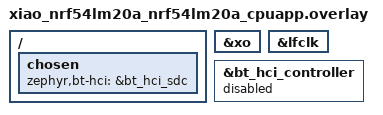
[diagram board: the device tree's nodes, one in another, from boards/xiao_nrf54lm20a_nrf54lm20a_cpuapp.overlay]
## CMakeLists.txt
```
# Copyright (c) 2026 Nordic Semiconductor ASA
#
# SPDX-License-Identifier: Apache-2.0

cmake_minimum_required(VERSION 3.20.0)

find_package(Zephyr REQUIRED HINTS $ENV{ZEPHYR_BASE})
project(bap_broadcast_assistant_display)

target_sources(app PRIVATE
  src/main.c
  src/ble_scan_ctrl.c
  src/ui.c
  src/nordic_logo.c
)
```

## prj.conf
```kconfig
# Copyright (c) 2026 Nordic Semiconductor ASA
#
# SPDX-License-Identifier: Apache-2.0

# General
CONFIG_LOG=y
CONFIG_MAIN_STACK_SIZE=8192
CONFIG_SYSTEM_WORKQUEUE_STACK_SIZE=4096

# Nordic's own reference boards for this SoC (nrf54lm20dk, nrf54l15dk) enable
# this by default in their board Kconfig.defconfig ("default
# ARCH_HAS_STACK_PROTECTION"); the XIAO board port never added that default,
# so a stack overflow on this board silently corrupts adjacent memory instead
# of being caught cleanly - manifesting as a confusing crash far from the
# actual cause (observed: "USAGE FAULT: Illegal load of EXC_RETURN into PC").
# Enabling it here turns any future overflow into a clear "stack overflow"
# fatal error instead.
CONFIG_HW_STACK_PROTECTION=y

# Bluetooth core
CONFIG_BT=y
CONFIG_BT_DEVICE_NAME="NCS Broadcast Assistant"
CONFIG_BT_CENTRAL=y
CONFIG_BT_GATT_CLIENT=y
CONFIG_BT_GATT_AUTO_DISCOVER_CCC=y
CONFIG_BT_GATT_AUTO_UPDATE_MTU=y
CONFIG_BT_SMP=y
CONFIG_BT_BUF_ACL_RX_SIZE=255
CONFIG_BT_BUF_ACL_TX_SIZE=251

# Both default to 1. Sinks stay connected once picked - toggling one between
# receiving and not receiving the source reuses its existing connection
# rather than reconnecting - so multiple sinks can be connected (and bonded)
# at once. Sized to BLE_SCAN_CTRL_MAX_SINK_CONN in ble_scan_ctrl.h, the most
# sinks this sample will ever try to hold open at the same time. Observed on
# hardware before this was raised: bonding a second sink while a first bond
# was still held failed synchronously with -ENOMEM.
CONFIG_BT_MAX_CONN=4
CONFIG_BT_MAX_PAIRED=4

# Explicitly require the Nordic SoftDevice Controller. This SoC's
# devicetree (plus boards/xiao_nrf54lm20a_nrf54lm20a_cpuapp.overlay, which
# disables the alternative &bt_hci_controller node) already makes this the
# Kconfig default, but pinning it here makes the choice self-documenting
# and keeps the build from silently falling back to Zephyr's open-source
# BT_LL_SW_SPLIT controller if the devicetree ever changes.
CONFIG_BT_LL_SOFTDEVICE=y
# Not CONFIG_BT_CTLR_SCAN_DATA_LEN_MAX: that symbol belongs to BT_LL_SW_SPLIT
# only, and does not apply to the SoftDevice Controller.

# LE Audio: Broadcast Assistant (BASS client) role
# CONFIG_UTF8 and CONFIG_BT_AUDIO gate the whole subsys/bluetooth/audio
# Kconfig tree (see zephyr/subsys/bluetooth/audio/Kconfig: "menuconfig
# BT_AUDIO depends on UTF8" followed by "if BT_AUDIO" wrapping Kconfig.bap).
# Without them, BT_BAP_BASS_MAX_SUBGROUPS and
# BT_AUDIO_CODEC_CFG_MAX_METADATA_SIZE below are never defined, which is
# why the build failed.
CONFIG_UTF8=y
CONFIG_BT_AUDIO=y
CONFIG_BT_EXT_ADV=y
CONFIG_BT_PER_ADV_SYNC=y
CONFIG_BT_ISO_SYNC_RECEIVER=y
CONFIG_BT_BAP_BROADCAST_ASSISTANT=y
CONFIG_BT_BAP_BASS_MAX_SUBGROUPS=2
CONFIG_BT_AUDIO_CODEC_CFG_MAX_METADATA_SIZE=255

# Display + touch input
CONFIG_DISPLAY=y
CONFIG_INPUT=y

# Real-time clock (PCF8563, wired up by the seeed_xiao_round_display shield's
# devicetree and aliased as "rtc") backing the idle clock screen.
CONFIG_RTC=y

# LVGL
CONFIG_LVGL=y
CONFIG_LV_Z_LVGL_MUTEX=y
CONFIG_LV_Z_MEM_POOL_SIZE=49152
CONFIG_LV_COLOR_DEPTH_16=y
CONFIG_LV_USE_LABEL=y
CONFIG_LV_USE_LIST=y
CONFIG_LV_USE_FLEX=y
CONFIG_LV_USE_BUTTON=y
CONFIG_LV_USE_BUTTONMATRIX=y
CONFIG_LV_USE_TEXTAREA=y
CONFIG_LV_USE_KEYBOARD=y
CONFIG_LV_USE_IMAGE=y
CONFIG_LV_USE_LINE=y
CONFIG_LV_FONT_MONTSERRAT_14=y
CONFIG_LV_FONT_MONTSERRAT_24=y
CONFIG_LV_FONT_DEFAULT_MONTSERRAT_14=y
```

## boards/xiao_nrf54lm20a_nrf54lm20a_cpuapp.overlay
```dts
/*
 * Copyright (c) 2026 Nordic Semiconductor ASA
 *
 * SPDX-License-Identifier: Apache-2.0
 */

/*
 * The XIAO nRF54LM20A board files (as of this NCS/Zephyr checkout) enable
 * &clock, &radio, &bt_hci_controller and &lfxo, but never set &xo or &lfclk
 * to "okay". The open-source Bluetooth Link Layer controller
 * (subsys/bluetooth/controller/ll_sw/nordic/lll/lll_clock.c) reads the
 * &lfclk node's "k32src-accuracy-ppm" property at compile time via a
 * DT_ENUM_IDX()-style macro; since the node is disabled it never appears in
 * the generated devicetree headers, so that macro is undeclared and the
 * build fails ("'__P_k32src_accuracy_ppm_IDX_0_ENUM_IDX' undeclared").
 *
 * Nordic's own reference boards for the same SoC (nrf54lm20dk, nrf54l15dk)
 * enable both nodes in their board devicetree; this overlay applies the same
 * fix at the application level without touching the shared board files.
 */

&xo {
	status = "okay";
};

&lfclk {
	status = "okay";
};

/*
 * zephyr/dts/arm/nordic/nrf54lm20_a_b_cpuapp.dtsi already enables
 * &bt_hci_sdc (the Nordic SoftDevice Controller) by default for this SoC.
 * The board's own nrf54lm20a_cpuapp_common.dtsi additionally enables
 * &bt_hci_controller (Zephyr's open-source software Link Layer controller,
 * compatible "zephyr,bt-hci-ll-sw-split"). With both devicetree nodes
 * "okay", Kconfig independently defaults BOTH CONFIG_BT_LL_SOFTDEVICE and
 * CONFIG_BT_LL_SW_SPLIT to y (nothing makes them mutually exclusive), so
 * both controller implementations get compiled and linked together and
 * collide on the same symbols (bt_ctlr_set_public_addr, bt_rand,
 * bt_encrypt_le/be): "multiple definition of `bt_ctlr_set_public_addr'".
 *
 * Disable the redundant open-source controller so only the SoftDevice
 * Controller (the production controller Nordic ships for this SoC) is
 * built.
 */
&bt_hci_controller {
	status = "disabled";
};

/*
 * nrf54lm20a_cpuapp_common.dtsi sets chosen "zephyr,bt-hci" to
 * &bt_hci_controller, which we just disabled above. Left unchanged, that
 * chosen property still points at a disabled node with no device instance,
 * so zephyr/subsys/bluetooth/host/hci_core.c's DEVICE_DT_GET(DT_CHOSEN(
 * zephyr_bt_hci)) fails to find the generated device: "'__device_dts_ord_N'
 * undeclared". Point it at &bt_hci_sdc instead, matching the controller we
 * actually kept enabled.
 */
/ {
	chosen {
		zephyr,bt-hci = &bt_hci_sdc;
	};
};
```

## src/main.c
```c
/*
 * Copyright (c) 2026 Nordic Semiconductor ASA
 *
 * SPDX-License-Identifier: Apache-2.0
 */

/**
 * @file
 * @brief Broadcast Assistant sample with a touch UI on a round display.
 *
 * Flow:
 *   0. Boots into an idle clock screen (Nordic logo + time). Tapping it
 *      starts scanning.
 *   1. Scan for Broadcast Sources and show them on screen.
 *   2. User taps a source -> periodic advertising sync to it starts in the
 *      background, and the UI switches to scanning for Broadcast Sinks.
 *      Tapping Exit at any point during 1-3 stops scanning/disconnects and
 *      returns to the clock screen.
 *   3. User taps a sink -> we connect to it, discover its Broadcast Audio
 *      Scan Service, and (once the source's BASE has been received) add the
 *      selected source to it, so the sink starts receiving the broadcast;
 *      it shows up greyed out and stays connected. Sink scanning keeps
 *      running, so more sinks can be picked the same way.
 *   4. Tapping a greyed-out sink removes the source from it over the same
 *      connection (no reconnect), so it stops receiving and goes back to
 *      being selectable. Tapping it again adds the source back. Either way
 *      the sink stays connected the whole time.
 */

#include <errno.h>
#include <stdbool.h>
#include <stdint.h>

#include <zephyr/kernel.h>
#include <zephyr/logging/log.h>

#include "ble_scan_ctrl.h"
#include "ui.h"

LOG_MODULE_REGISTER(app, LOG_LEVEL_INF);

#define UI_POLL_PERIOD	   K_MSEC(10)
#define SPLASH_DURATION_MS 2000U

static void handle_row_selected(enum ui_screen screen, uint8_t index);
static void handle_clock_tapped(void);
static void handle_exit(void);
static void handle_source_found(uint8_t index, const struct ble_broadcast_source *source);
static void handle_sink_found(uint8_t index, const struct ble_broadcast_sink *sink);
static void handle_sink_connected(uint8_t index);
static void handle_sink_disconnected(uint8_t index);
static void handle_source_synced(void);
static void handle_source_added(uint8_t index);
static void handle_source_removed(uint8_t index);
static void handle_op_failed(enum ble_scan_ctrl_op op, uint8_t sink_index, int err);

static const struct ble_scan_ctrl_cb ble_callbacks = {
	.source_found = handle_source_found,
	.sink_found = handle_sink_found,
	.sink_connected = handle_sink_connected,
	.sink_disconnected = handle_sink_disconnected,
	.source_synced = handle_source_synced,
	.source_added = handle_source_added,
	.source_removed = handle_source_removed,
	.op_failed = handle_op_failed,
};

/** Drop all BLE state and restart the whole demo from the source-scan screen. */
static void restart_demo(void)
{
	int ret;

	(void)ble_scan_ctrl_reset();
	ui_show_source_list();

	ret = ble_scan_ctrl_start_source_scan();
	if (ret != 0) {
		LOG_ERR("Failed to start source scan (ret %d)", ret);
		ui_show_status("Scan error", "Could not start source scan");
	}
}

/** True for failures that mean the selected source itself is gone, not just one sink. */
static bool op_is_source_level(enum ble_scan_ctrl_op op)
{
	return op == BLE_SCAN_CTRL_OP_SOURCE_SCAN || op == BLE_SCAN_CTRL_OP_SOURCE_PA_SYNC;
}

static void handle_row_selected(enum ui_screen screen, uint8_t index)
{
	int ret;

	switch (screen) {
	case UI_SCREEN_SOURCE_LIST:
		ret = ble_scan_ctrl_select_source(index);
		if (ret != 0) {
			LOG_ERR("Failed to select source %u (ret %d)", index, ret);
			ui_show_status("Selection failed", "Could not select that source");
			return;
		}

		LOG_INF("Source %u selected; scanning for sinks", index);
		ui_show_sink_list();

		ret = ble_scan_ctrl_start_sink_scan();
		if (ret != 0) {
			LOG_ERR("Failed to start sink scan (ret %d)", ret);
			ui_show_status("Scan error", "Could not start sink scan");
		}
		break;

	case UI_SCREEN_SINK_LIST:
		/* Connects a never-seen sink, or toggles an already-connected one between
		 * receiving and not receiving the source - see ble_scan_ctrl_select_sink().
		 * Every outcome (including failure) arrives later via one of the
		 * ble_callbacks below, keyed by sink index, so there is nothing to do here
		 * beyond starting it and quietly dropping a redundant tap.
		 */
		ret = ble_scan_ctrl_select_sink(index);
		if (ret == -EBUSY) {
			LOG_WRN("Sink %u already has an operation in progress", index);
		} else if (ret != 0) {
			LOG_ERR("Failed to toggle sink %u (ret %d)", index, ret);
		}
		break;

	case UI_SCREEN_CLOCK:
	case UI_SCREEN_STATUS:
	default:
		/* No tappable rows on these screens; nothing to do. */
		break;
	}
}

static void handle_clock_tapped(void)
{
	LOG_INF("Clock tapped; starting scan");
	restart_demo();
}

static void handle_exit(void)
{
	LOG_INF("Exit tapped; returning to clock");
	(void)ble_scan_ctrl_reset();
	ui_show_clock();
}

static void handle_source_found(uint8_t index, const struct ble_broadcast_source *source)
{
	if (source == NULL) {
		return;
	}

	LOG_INF("Source[%u]: %s (id 0x%06x)", index, source->name, source->broadcast_id);
	(void)ui_add_source_row(source->name, source->broadcast_id);
}

static void handle_sink_found(uint8_t index, const struct ble_broadcast_sink *sink)
{
	if (sink == NULL) {
		return;
	}

	LOG_INF("Sink[%u]: %s", index, sink->name);
	(void)ui_add_sink_row(sink->name);
}

static void handle_sink_connected(uint8_t index)
{
	LOG_INF("Sink %u connected and its Broadcast Audio Scan Service was discovered", index);
}

static void handle_sink_disconnected(uint8_t index)
{
	LOG_WRN("Sink %u disconnected unexpectedly", index);
	ui_set_sink_configured(index, false);
}

static void handle_source_synced(void)
{
	LOG_INF("Periodic advertising synced to the selected source");
}

static void handle_source_added(uint8_t index)
{
	LOG_INF("Source added to sink %u; it is now receiving the broadcast", index);
	ui_set_sink_configured(index, true);
}

static void handle_source_removed(uint8_t index)
{
	LOG_INF("Source removed from sink %u; it stopped receiving the broadcast", index);
	ui_set_sink_configured(index, false);
}

/*
 * BLE_SCAN_CTRL_OP_SOURCE_SCAN/SOURCE_PA_SYNC mean the selected source itself is gone
 * (never found, or its periodic advertising sync was lost - source switched off, went
 * out of range, or the controller gave up) - nothing to preserve, so restart from
 * scratch. Every other op is specific to one sink (its own connect/security/BASS/
 * add-source/remove-source step) and does not affect the source or any other sink, so
 * just log it - that sink's row already reflects reality (still, or not yet, greyed
 * out) since a failed add/remove leaves ble_scan_ctrl's own state unchanged.
 */
static void handle_op_failed(enum ble_scan_ctrl_op op, uint8_t sink_index, int err)
{
	if (op_is_source_level(op)) {
		LOG_ERR("Operation %d failed (err %d)", (int)op, err);
		restart_demo();
		return;
	}

	LOG_ERR("Operation %d failed for sink %u (err %d)", (int)op, sink_index, err);
}

/** Keep driving the LVGL loop for at least duration_ms without blocking it. */
static void pump_ui_for(uint32_t duration_ms)
{
	int64_t deadline = k_uptime_get() + duration_ms;

	do {
		ui_process();
		k_sleep(UI_POLL_PERIOD);
	} while (k_uptime_get() < deadline);
}

int main(void)
{
	int ret;

	ret = ui_init(handle_row_selected, handle_clock_tapped, handle_exit);
	if (ret != 0) {
		LOG_ERR("Failed to initialize UI (ret %d)", ret);
		return 0;
	}

	ret = ble_scan_ctrl_init(&ble_callbacks);
	if (ret != 0) {
		LOG_ERR("Failed to initialize Broadcast Assistant control (ret %d)", ret);
		return 0;
	}

	ui_show_splash();
	pump_ui_for(SPLASH_DURATION_MS);

	ui_show_clock();

	while (true) {
		ui_process();
		k_sleep(UI_POLL_PERIOD);
	}

	return 0;
}
```

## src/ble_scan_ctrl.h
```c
/*
 * Copyright (c) 2026 Nordic Semiconductor ASA
 *
 * SPDX-License-Identifier: Apache-2.0
 */

/**
 * @file
 * @brief Bluetooth LE Audio Broadcast Assistant control logic.
 *
 * This module implements the BAP Broadcast Assistant role: it scans for
 * Broadcast Sources (LE Audio broadcasters), scans for Broadcast Sinks
 * (devices implementing a BASS server / Scan Delegator role), connects to
 * selected sinks, and toggles whether each one is configured (via the
 * Broadcast Audio Scan Service) to synchronize to the selected source.
 *
 * Sinks stay connected once picked, for as long as their connection holds up:
 * toggling a sink between receiving and not receiving the source only ever
 * adds or removes it from that sink's Broadcast Audio Scan Service over the
 * existing connection, never reconnects. Several sinks can be connected and
 * independently toggled at the same time, up to @ref BLE_SCAN_CTRL_MAX_SINK_CONN.
 *
 * All public functions may be called from any single application thread
 * (the application must not call them concurrently from multiple threads).
 * All callbacks in @ref ble_scan_ctrl_cb are invoked from Bluetooth stack
 * context (the system workqueue or the Bluetooth RX thread) and must not
 * block.
 */

#ifndef BLE_SCAN_CTRL_H_
#define BLE_SCAN_CTRL_H_

#include <stdbool.h>
#include <stdint.h>

#include <zephyr/bluetooth/addr.h>

#ifdef __cplusplus
extern "C" {
#endif

/** Maximum length, including the terminating NUL, of a cached device name. */
#define BLE_SCAN_CTRL_NAME_LEN 32U

/** Maximum number of distinct sources/sinks tracked for one selected source. */
#define BLE_SCAN_CTRL_MAX_RESULTS 8U

/** Maximum number of sinks that may be connected (and independently toggled) at once. */
#define BLE_SCAN_CTRL_MAX_SINK_CONN 4U

/** Information describing a discovered Broadcast Source (LE Audio broadcaster). */
struct ble_broadcast_source {
	/** Best-effort display name (Bluetooth name or Broadcast Name). Always NUL-terminated. */
	char name[BLE_SCAN_CTRL_NAME_LEN];
	/** 24-bit Broadcast ID advertised by the source. */
	uint32_t broadcast_id;
	/** Advertiser address. */
	bt_addr_le_t addr;
	/** Advertising Set ID of the source's extended advertising set. */
	uint8_t sid;
	/** Periodic advertising interval, or BT_BAP_PA_INTERVAL_UNKNOWN. */
	uint16_t pa_interval;
};

/** Information describing a discovered Broadcast Sink (BASS server / Scan Delegator). */
struct ble_broadcast_sink {
	/** Best-effort display name (Bluetooth name). Always NUL-terminated. */
	char name[BLE_SCAN_CTRL_NAME_LEN];
	/** Connectable advertiser address. */
	bt_addr_le_t addr;
};

/** Identifies which asynchronous operation an error report in @ref ble_scan_ctrl_cb refers to. */
enum ble_scan_ctrl_op {
	BLE_SCAN_CTRL_OP_SOURCE_SCAN,
	BLE_SCAN_CTRL_OP_SINK_SCAN,
	BLE_SCAN_CTRL_OP_SINK_CONNECT,
	BLE_SCAN_CTRL_OP_SINK_SECURITY,
	BLE_SCAN_CTRL_OP_BASS_DISCOVER,
	BLE_SCAN_CTRL_OP_SOURCE_PA_SYNC,
	BLE_SCAN_CTRL_OP_ADD_SOURCE,
	BLE_SCAN_CTRL_OP_REMOVE_SOURCE,
};

/**
 * @brief Application event callbacks.
 *
 * Every member is optional; leave it NULL if the event is not of interest.
 * See the file-level comment for the threading contract. Every callback that
 * takes a sink @p index reports it as the index into the list of sinks
 * reported since the last call to ble_scan_ctrl_start_sink_scan(), same as
 * the index passed in to ble_scan_ctrl_select_sink().
 */
struct ble_scan_ctrl_cb {
	/** A new, previously unseen Broadcast Source was found while source-scanning. */
	void (*source_found)(uint8_t index, const struct ble_broadcast_source *source);
	/** A new, previously unseen Broadcast Sink was found while sink-scanning. */
	void (*sink_found)(uint8_t index, const struct ble_broadcast_sink *sink);
	/** The sink is connected, secured, and its BASS has been discovered. */
	void (*sink_connected)(uint8_t index);
	/** The sink connection was lost (or explicitly closed); it is no longer configured. */
	void (*sink_disconnected)(uint8_t index);
	/** Periodic advertising to the selected source is synced and its BASE was parsed. */
	void (*source_synced)(void);
	/** The source was added to the sink's Broadcast Audio Scan Service; it is receiving. */
	void (*source_added)(uint8_t index);
	/** The source was removed from the sink's Broadcast Audio Scan Service. */
	void (*source_removed)(uint8_t index);
	/**
	 * @brief An asynchronous operation failed.
	 *
	 * @p sink_index is only meaningful for sink-specific ops (anything other than
	 * BLE_SCAN_CTRL_OP_SOURCE_SCAN/SOURCE_PA_SYNC); ignore it otherwise.
	 */
	void (*op_failed)(enum ble_scan_ctrl_op op, uint8_t sink_index, int err);
};

/**
 * @brief Initialize the Broadcast Assistant control module.
 *
 * Enables the Bluetooth stack and registers all internal callbacks. Must be
 * called exactly once, before any other function in this module.
 *
 * @param cb Application callback structure. Must remain valid for the
 *           lifetime of the program. Must not be NULL.
 *
 * @retval 0 on success.
 * @retval -EINVAL if @p cb is NULL.
 * @retval Negative errno from bt_enable() on Bluetooth init failure.
 */
int ble_scan_ctrl_init(const struct ble_scan_ctrl_cb *cb);

/**
 * @brief Start scanning for Broadcast Sources.
 *
 * Clears any previously discovered source list. Discovered sources are
 * reported through @ref ble_scan_ctrl_cb.source_found.
 *
 * @retval 0 on success.
 * @retval Negative errno on failure to start scanning.
 */
int ble_scan_ctrl_start_source_scan(void);

/**
 * @brief Start scanning for Broadcast Sinks.
 *
 * Clears any previously discovered sink list. Discovered sinks are reported
 * through @ref ble_scan_ctrl_cb.sink_found. Keeps running (sinks can keep
 * being discovered) alongside any connections made via
 * ble_scan_ctrl_select_sink(), until ble_scan_ctrl_reset() is called.
 *
 * @retval 0 on success.
 * @retval Negative errno on failure to start scanning.
 */
int ble_scan_ctrl_start_sink_scan(void);

/**
 * @brief Select a previously discovered Broadcast Source.
 *
 * Stops scanning and begins periodic advertising sync to the selected
 * source in the background in order to obtain its BASE (subgroup) data.
 *
 * @param index Zero-based index into the list of sources reported since the
 *              last call to ble_scan_ctrl_start_source_scan().
 *
 * @retval 0 on success.
 * @retval -EINVAL if @p index is out of range.
 * @retval Negative errno on failure to create the periodic advertising sync.
 */
int ble_scan_ctrl_select_source(uint8_t index);

/**
 * @brief Toggle a previously discovered Broadcast Sink.
 *
 * Behavior depends on the sink's current state:
 * - Never connected: connects to it (subject to
 *   @ref BLE_SCAN_CTRL_MAX_SINK_CONN), discovers its Broadcast Audio Scan
 *   Service, and once the selected source has been PA-synced, adds it -
 *   the connection is kept afterwards.
 * - Connected and currently receiving the source: removes the source from
 *   its Broadcast Audio Scan Service over the existing connection (no
 *   reconnect), so it stops receiving but stays connected.
 * - Connected and not currently receiving the source: adds the source back
 *   over the existing connection (no reconnect).
 *
 * Every outcome is reported asynchronously through @ref ble_scan_ctrl_cb
 * (sink_connected, source_added, source_removed, or op_failed) rather than
 * through this function's return value, which only reports whether the
 * requested step could be *started*.
 *
 * @param index Zero-based index into the list of sinks reported since the
 *              last call to ble_scan_ctrl_start_sink_scan().
 *
 * @retval 0 on success.
 * @retval -EINVAL if @p index is out of range.
 * @retval -EBUSY if an operation on that sink is already in progress.
 * @retval -ENOMEM if @ref BLE_SCAN_CTRL_MAX_SINK_CONN connections are already in use.
 * @retval Negative errno on failure to start the connection/add/remove step.
 */
int ble_scan_ctrl_select_sink(uint8_t index);

/**
 * @brief Reset all state back to idle.
 *
 * Stops any ongoing scan, disconnects every connected sink, deletes the
 * periodic advertising sync (if any), and clears all discovered/selected
 * data. Safe to call at any time, including when already idle.
 *
 * @retval 0 always.
 */
int ble_scan_ctrl_reset(void);

#ifdef __cplusplus
}
#endif

#endif /* BLE_SCAN_CTRL_H_ */
```

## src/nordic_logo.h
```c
/*
 * Copyright (c) 2026 Nordic Semiconductor ASA
 *
 * SPDX-License-Identifier: Apache-2.0
 */

#ifndef NORDIC_LOGO_H_
#define NORDIC_LOGO_H_

#include <stdint.h>

#include <lvgl.h>

#ifdef __cplusplus
extern "C" {
#endif

/** Nordic Semiconductor logo, 110x95 RGB565, flattened onto white. */
extern const lv_image_dsc_t nordic_logo;

#ifdef __cplusplus
}
#endif

#endif /* NORDIC_LOGO_H_ */
```

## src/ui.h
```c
/*
 * Copyright (c) 2026 Nordic Semiconductor ASA
 *
 * SPDX-License-Identifier: Apache-2.0
 */

/**
 * @file
 * @brief Touch UI for the Seeed Studio XIAO Round Display.
 *
 * Renders a scrollable, tappable list of scan results and a status screen.
 * This module owns all LVGL interaction; callers never touch LVGL objects
 * directly. It is safe to call the "mutating" functions below (everything
 * except ui_process()) from a thread other than the one that calls
 * ui_process(), since they take the LVGL lock internally.
 */

#ifndef UI_H_
#define UI_H_

#include <stdbool.h>
#include <stdint.h>

#ifdef __cplusplus
extern "C" {
#endif

/** Maximum number of rows the list screens can display at once. */
#define UI_MAX_LIST_ITEMS 8U

/** Which screen a row-tap event in @ref ui_row_selected_cb occurred on. */
enum ui_screen {
	UI_SCREEN_CLOCK,
	UI_SCREEN_SOURCE_LIST,
	UI_SCREEN_SINK_LIST,
	UI_SCREEN_STATUS,
};

/**
 * @brief Row-tap callback.
 *
 * Invoked from the thread that calls ui_process(). @p index is guaranteed
 * to be less than the number of rows currently shown on @p screen.
 *
 * @param screen Screen the tap occurred on.
 * @param index  Zero-based row index within that screen's list.
 */
typedef void (*ui_row_selected_cb)(enum ui_screen screen, uint8_t index);

/** Invoked from the thread that calls ui_process() when the clock screen is tapped. */
typedef void (*ui_clock_tapped_cb)(void);

/** Invoked from the thread that calls ui_process() when the Exit button is tapped. */
typedef void (*ui_exit_cb)(void);

/**
 * @brief Initialize the display and build the UI.
 *
 * Must be called once, from the thread that will subsequently call
 * ui_process() in a loop.
 *
 * @param on_row_selected Callback invoked when the user taps a list row.
 *                        Must not be NULL.
 * @param on_clock_tapped Callback invoked when the user taps the clock
 *                        screen (request to start scanning). Must not be
 *                        NULL.
 * @param on_exit         Callback invoked when the user taps the Exit
 *                        button on a list screen (request to return to the
 *                        clock screen). Must not be NULL.
 *
 * @retval 0 on success.
 * @retval -EINVAL if any callback is NULL.
 * @retval -ENODEV if the display device is not ready.
 * @retval Negative errno on other display initialization failures.
 */
int ui_init(ui_row_selected_cb on_row_selected, ui_clock_tapped_cb on_clock_tapped,
	    ui_exit_cb on_exit);

/**
 * @brief Show the startup splash screen.
 *
 * Displays the Nordic Semiconductor logo. The caller is responsible for
 * timing: keep calling ui_process() for as long as the splash should stay
 * on screen, then switch away with ui_show_clock() or similar.
 */
void ui_show_splash(void);

/**
 * @brief Show the idle clock screen.
 *
 * Displays the Nordic Semiconductor logo and the current time (read from
 * the board's RTC, if one is available), and waits for a tap to invoke the
 * on_clock_tapped callback passed to ui_init().
 */
void ui_show_clock(void);

/** Switch to the (initially empty) Broadcast Source list screen. */
void ui_show_source_list(void);

/** Switch to the (initially empty) Broadcast Sink list screen. */
void ui_show_sink_list(void);

/**
 * @brief Append one row to the Broadcast Source list.
 *
 * @param name         Display name; may be empty but must not be NULL.
 * @param broadcast_id 24-bit broadcast ID shown alongside the name.
 *
 * @retval 0 on success.
 * @retval -EINVAL if @p name is NULL.
 * @retval -ENOMEM if the list already holds UI_MAX_LIST_ITEMS rows.
 */
int ui_add_source_row(const char *name, uint32_t broadcast_id);

/**
 * @brief Append one row to the Broadcast Sink list, shown normally (not yet receiving).
 *
 * @param name Display name; may be empty but must not be NULL.
 *
 * @retval 0 on success.
 * @retval -EINVAL if @p name is NULL.
 * @retval -ENOMEM if the list already holds UI_MAX_LIST_ITEMS rows.
 */
int ui_add_sink_row(const char *name);

/**
 * @brief Update whether a sink row is shown greyed out (currently receiving the source).
 *
 * The row stays tappable either way; tapping it is what toggles this in the first place -
 * this function only reflects that outcome once it is known, it does not cause it.
 *
 * @param index Index this row was reported with (by ui_row_selected_cb, and matching
 *              ble_scan_ctrl's own sink index).
 * @param configured True to show it greyed out, false to show it normally.
 */
void ui_set_sink_configured(uint8_t index, bool configured);

/**
 * @brief Switch to the status screen and show a short message.
 *
 * @param title  Short headline; must not be NULL.
 * @param detail Longer description, or NULL to show no detail text.
 */
void ui_show_status(const char *title, const char *detail);

/** Drive the LVGL timer/render loop. Call periodically from one dedicated thread. */
void ui_process(void);

#ifdef __cplusplus
}
#endif

#endif /* UI_H_ */
```
